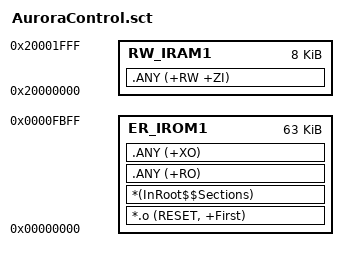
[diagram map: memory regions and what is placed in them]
; 64 KiB Flash中最后1 KiB保留给双页参数存储：0xFC00～0xFFFF。
LR_IROM1 0x00000000 0x0000FC00
{
    ER_IROM1 0x00000000 0x0000FC00
    {
        *.o (RESET, +First)
        *(InRoot$$Sections)
        .ANY (+RO)
        .ANY (+XO)
    }
    RW_IRAM1 0x20000000 0x00002000
    {
        .ANY (+RW +ZI)
    }
}
